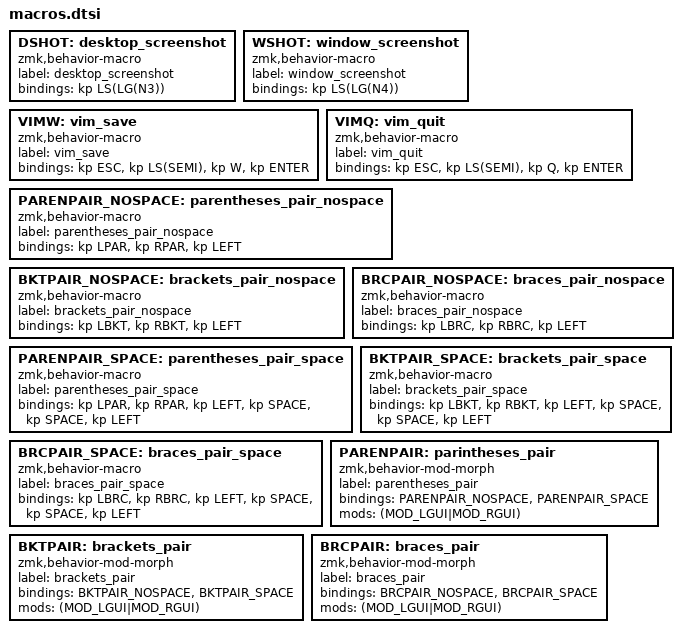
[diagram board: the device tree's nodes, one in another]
DSHOT: desktop_screenshot {
  compatible = "zmk,behavior-macro";
  label = "desktop_screenshot";
  #binding-cells = <0>;
  bindings = <&kp LS(LG(N3))>; // <&kp ..>, <&kp ..>
};
WSHOT: window_screenshot {
  compatible = "zmk,behavior-macro";
  label = "window_screenshot";
  #binding-cells = <0>;
  bindings = <&kp LS(LG(N4))>;
};
VIMW: vim_save {
  compatible = "zmk,behavior-macro";
  label = "vim_save";
  #binding-cells = <0>;
  bindings = <&kp ESC>, <&kp LS(SEMI)>, <&kp W>, <&kp ENTER>;
};
VIMQ: vim_quit {
  compatible = "zmk,behavior-macro";
  label = "vim_quit";
  #binding-cells = <0>;
  bindings = <&kp ESC>, <&kp LS(SEMI)>, <&kp Q>, <&kp ENTER>;
};


PARENPAIR_NOSPACE: parentheses_pair_nospace {
  compatible = "zmk,behavior-macro";
  label = "parentheses_pair_nospace";
  #binding-cells = <0>;
  bindings = <&kp LPAR>, <&kp RPAR>, <&kp LEFT>;
};
BKTPAIR_NOSPACE: brackets_pair_nospace {
  compatible = "zmk,behavior-macro";
  label = "brackets_pair_nospace";
  #binding-cells = <0>;
  bindings = <&kp LBKT>, <&kp RBKT>, <&kp LEFT>;
};
BRCPAIR_NOSPACE: braces_pair_nospace {
  compatible = "zmk,behavior-macro";
  label = "braces_pair_nospace";
  #binding-cells = <0>;
  bindings = <&kp LBRC>, <&kp RBRC>, <&kp LEFT>;
};

PARENPAIR_SPACE: parentheses_pair_space {
  compatible = "zmk,behavior-macro";
  label = "parentheses_pair_space";
  #binding-cells = <0>;
  bindings = <&kp LPAR>, <&kp RPAR>, <&kp LEFT>, <&kp SPACE>, <&kp SPACE>, <&kp LEFT>;
};
BKTPAIR_SPACE: brackets_pair_space {
  compatible = "zmk,behavior-macro";
  label = "brackets_pair_space";
  #binding-cells = <0>;
  bindings = <&kp LBKT>, <&kp RBKT>, <&kp LEFT>, <&kp SPACE>, <&kp SPACE>, <&kp LEFT>;
};
BRCPAIR_SPACE: braces_pair_space {
  compatible = "zmk,behavior-macro";
  label = "braces_pair_space";
  #binding-cells = <0>;
  bindings = <&kp LBRC>, <&kp RBRC>, <&kp LEFT>, <&kp SPACE>, <&kp SPACE>, <&kp LEFT>;
};

PARENPAIR: parintheses_pair {
    compatible = "zmk,behavior-mod-morph";
    label = "parentheses_pair";
    #binding-cells = <0>;
    bindings = <&PARENPAIR_NOSPACE>, <&PARENPAIR_SPACE>;
    mods = <(MOD_LGUI|MOD_RGUI)>;
};
BKTPAIR: brackets_pair {
    compatible = "zmk,behavior-mod-morph";
    label = "brackets_pair";
    #binding-cells = <0>;
    bindings = <&BKTPAIR_NOSPACE>, <&BKTPAIR_SPACE>;
    mods = <(MOD_LGUI|MOD_RGUI)>;
};
BRCPAIR: braces_pair {
    compatible = "zmk,behavior-mod-morph";
    label = "braces_pair";
    #binding-cells = <0>;
    bindings = <&BRCPAIR_NOSPACE>, <&BRCPAIR_SPACE>;
    mods = <(MOD_LGUI|MOD_RGUI)>;
};
